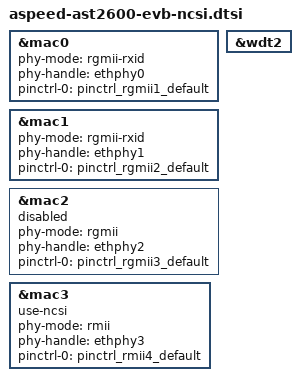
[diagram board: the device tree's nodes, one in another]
// SPDX-License-Identifier: GPL-2.0-or-later
// Copyright 2019 IBM Corp.

&mac0 {
	status = "okay";

	phy-mode = "rgmii-rxid";
	phy-handle = <&ethphy0>;

	pinctrl-names = "default";
	pinctrl-0 = <&pinctrl_rgmii1_default>;
};


&mac1 {
	status = "okay";

	phy-mode = "rgmii-rxid";
	phy-handle = <&ethphy1>;

	pinctrl-names = "default";
	pinctrl-0 = <&pinctrl_rgmii2_default>;
};

&mac2 {
	status = "disabled";

	phy-mode = "rgmii";
	phy-handle = <&ethphy2>;

	pinctrl-names = "default";
	pinctrl-0 = <&pinctrl_rgmii3_default>;
};

&mac3 {
	status = "okay";
	use-ncsi;
	phy-mode = "rmii";
	phy-handle = <&ethphy3>;

	pinctrl-names = "default";
	pinctrl-0 = <&pinctrl_rmii4_default>;
};

&wdt2 {
       status = "okay";
};
